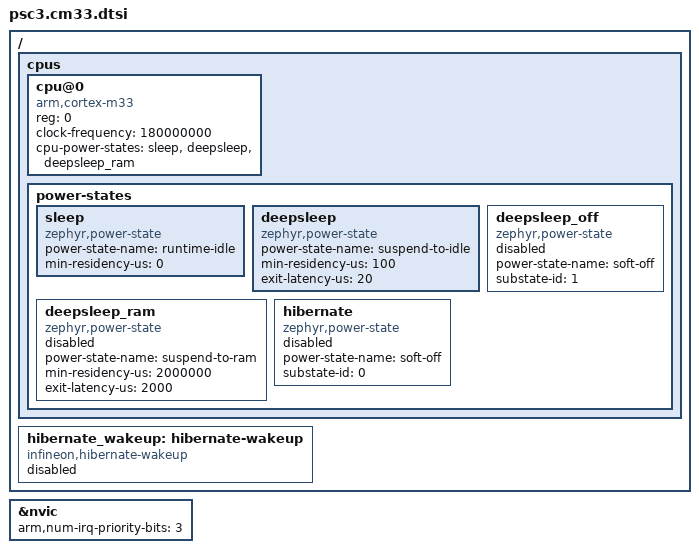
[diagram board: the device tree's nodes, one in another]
/*
 * SPDX-FileCopyrightText: Copyright (c) 2026 Infineon Technologies AG,
 * SPDX-FileCopyrightText: or an affiliate of Infineon Technologies AG. All rights reserved.
 *
 * SPDX-License-Identifier: Apache-2.0
 */

#include <arm/armv8-m.dtsi>

/ {
	cpus {
		#address-cells = <1>;
		#size-cells = <0>;

		cpu@0 {
			device_type = "cpu";
			compatible = "arm,cortex-m33";
			reg = <0>;
			clock-frequency = <180000000>;
			cpu-power-states = <&sleep &deepsleep &deepsleep_ram>;
		};

		power-states {
			sleep: sleep {
				compatible = "zephyr,power-state";
				power-state-name = "runtime-idle";
				min-residency-us = <0>;
			};

			deepsleep: deepsleep {
				compatible = "zephyr,power-state";
				power-state-name = "suspend-to-idle";
				min-residency-us = <100>;
				exit-latency-us = <20>;
			};

			deepsleep_ram: deepsleep_ram {
				compatible = "zephyr,power-state";
				power-state-name = "suspend-to-ram";
				min-residency-us = <2000000>;
				exit-latency-us = <2000>;
				status = "disabled";
			};

			deepsleep_off: deepsleep_off {
				compatible = "zephyr,power-state";
				power-state-name = "soft-off";
				substate-id = <1>;
				status = "disabled";
			};

			hibernate: hibernate {
				compatible = "zephyr,power-state";
				power-state-name = "soft-off";
				substate-id = <0>;
				status = "disabled";
			};
		};
	};

	/*
	 * Dedicated Hibernate wakeup sources.  Disabled by default; a board or
	 * application enables this node and selects the trigger(s) it needs.  The
	 * The pin-to-pad mapping is fixed in silicon: PIN0 = P2.0, PIN1 = P9.0.
	 */
	hibernate_wakeup: hibernate-wakeup {
		compatible = "infineon,hibernate-wakeup";
		status = "disabled";
	};
};

&nvic {
	arm,num-irq-priority-bits = <3>;
};
